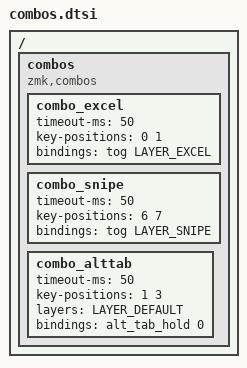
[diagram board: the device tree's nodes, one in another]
/*
 * Combos for sticky / hold layers without spending a dedicated button.
 *
 * Excel: top two buttons (pos 0+1) toggle-lock; leave with Back
 * (&to LAYER_DEFAULT) on that layer.
 * Snipe: lower two buttons (pos 6+7) toggle-lock (momentary snipe stays on
 * hold of Close / &snlk).
 * Alt+Tab: Esc + Copy/Paste (pos 1+3) hold — Alt down + LAYER_ALTTAB until
 * release (left encoder Tab / Shift+Tab).
 *
 * LAYER_EXCEL / LAYER_SNIPE / LAYER_ALTTAB must be defined before include.
 */

/ {
	combos {
		compatible = "zmk,combos";

		combo_excel {
			timeout-ms = <50>;
			key-positions = <0 1>;
			bindings = <&tog LAYER_EXCEL>;
		};

		combo_snipe {
			timeout-ms = <50>;
			key-positions = <6 7>;
			bindings = <&tog LAYER_SNIPE>;
		};

		combo_alttab {
			timeout-ms = <50>;
			key-positions = <1 3>;
			layers = <LAYER_DEFAULT>;
			bindings = <&alt_tab_hold 0>;
		};
	};
};
